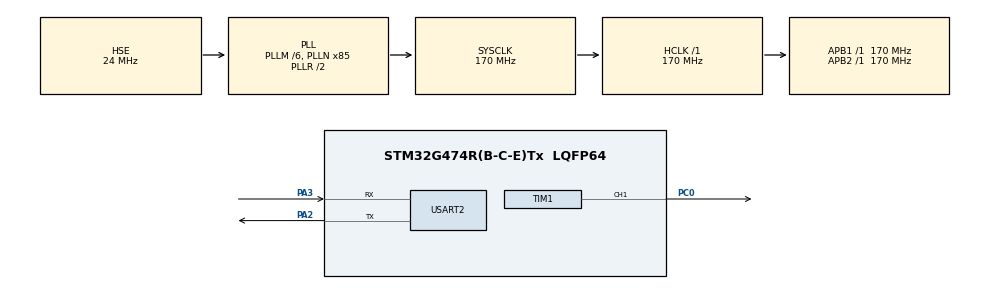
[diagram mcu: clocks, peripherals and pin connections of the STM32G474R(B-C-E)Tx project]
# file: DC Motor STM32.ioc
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Dma.Request0=TIM1_CH1
Dma.Request1=USART2_RX
Dma.Request2=USART2_TX
Dma.TIM1_CH1.0.Direction=DMA_MEMORY_TO_PERIPH
Dma.TIM1_CH1.0.EventEnable=DISABLE
Dma.TIM1_CH1.0.Instance=DMA1_Channel1
Dma.TIM1_CH1.0.MemDataAlignment=DMA_MDATAALIGN_HALFWORD
Dma.TIM1_CH1.0.MemInc=DMA_MINC_ENABLE
Dma.TIM1_CH1.0.Mode=DMA_NORMAL
Dma.TIM1_CH1.0.PeriphDataAlignment=DMA_PDATAALIGN_HALFWORD
Dma.TIM1_CH1.0.PeriphInc=DMA_PINC_DISABLE
Dma.TIM1_CH1.0.Polarity=HAL_DMAMUX_REQ_GEN_RISING
Dma.TIM1_CH1.0.Priority=DMA_PRIORITY_LOW
Dma.TIM1_CH1.0.RequestNumber=1
Dma.TIM1_CH1.0.SignalID=NONE
Dma.TIM1_CH1.0.SyncEnable=DISABLE
Dma.TIM1_CH1.0.SyncPolarity=HAL_DMAMUX_SYNC_NO_EVENT
Dma.TIM1_CH1.0.SyncRequestNumber=1
Dma.TIM1_CH1.0.SyncSignalID=NONE
Dma.USART2_RX.1.Direction=DMA_PERIPH_TO_MEMORY
Dma.USART2_RX.1.EventEnable=DISABLE
Dma.USART2_RX.1.Instance=DMA1_Channel2
Dma.USART2_RX.1.MemDataAlignment=DMA_MDATAALIGN_BYTE
Dma.USART2_RX.1.MemInc=DMA_MINC_ENABLE
Dma.USART2_RX.1.Mode=DMA_NORMAL
Dma.USART2_RX.1.PeriphDataAlignment=DMA_PDATAALIGN_BYTE
Dma.USART2_RX.1.PeriphInc=DMA_PINC_DISABLE
Dma.USART2_RX.1.Polarity=HAL_DMAMUX_REQ_GEN_RISING
Dma.USART2_RX.1.Priority=DMA_PRIORITY_LOW
Dma.USART2_RX.1.RequestNumber=1
Dma.USART2_RX.1.SignalID=NONE
Dma.USART2_RX.1.SyncEnable=DISABLE
Dma.USART2_RX.1.SyncPolarity=HAL_DMAMUX_SYNC_NO_EVENT
Dma.USART2_RX.1.SyncRequestNumber=1
Dma.USART2_RX.1.SyncSignalID=NONE
Dma.USART2_TX.2.Direction=DMA_MEMORY_TO_PERIPH
Dma.USART2_TX.2.EventEnable=DISABLE
Dma.USART2_TX.2.Instance=DMA1_Channel3
Dma.USART2_TX.2.MemDataAlignment=DMA_MDATAALIGN_BYTE
Dma.USART2_TX.2.MemInc=DMA_MINC_ENABLE
Dma.USART2_TX.2.Mode=DMA_NORMAL
Dma.USART2_TX.2.PeriphDataAlignment=DMA_PDATAALIGN_BYTE
Dma.USART2_TX.2.PeriphInc=DMA_PINC_DISABLE
Dma.USART2_TX.2.Polarity=HAL_DMAMUX_REQ_GEN_RISING
Dma.USART2_TX.2.Priority=DMA_PRIORITY_LOW
Dma.USART2_TX.2.RequestNumber=1
Dma.USART2_TX.2.SignalID=NONE
Dma.USART2_TX.2.SyncEnable=DISABLE
Dma.USART2_TX.2.SyncPolarity=HAL_DMAMUX_SYNC_NO_EVENT
Dma.USART2_TX.2.SyncRequestNumber=1
Dma.USART2_TX.2.SyncSignalID=NONE
Mcu.Family=STM32G4
Mcu.Name=STM32G474R(B-C-E)Tx
Mcu.Package=LQFP64
NVIC.DMA1_Channel1_IRQn=true\:0\:0\:false\:false\:true\:false\:true\:true
NVIC.DMA1_Channel2_IRQn=true\:0\:0\:false\:false\:true\:false\:true\:true
NVIC.DMA1_Channel3_IRQn=true\:0\:0\:false\:false\:true\:false\:true\:true
NVIC.PriorityGroup=NVIC_PRIORITYGROUP_4
NVIC.USART2_IRQn=true\:0\:0\:false\:false\:true\:true\:true\:true
PA13.Mode=Serial_Wire
PA13.Signal=SYS_JTMS-SWDIO
PA14.Mode=Serial_Wire
PA14.Signal=SYS_JTCK-SWCLK
PA2.Mode=Asynchronous
PA2.Signal=USART2_TX
PA3.Mode=Asynchronous
PA3.Signal=USART2_RX
PC0.Signal=S_TIM1_CH1
PC14-OSC32_IN.Mode=LSE-External-Oscillator
PC14-OSC32_IN.Signal=RCC_OSC32_IN
PC15-OSC32_OUT.Mode=LSE-External-Oscillator
PC15-OSC32_OUT.Signal=RCC_OSC32_OUT
PF0-OSC_IN.Mode=HSE-External-Oscillator
PF0-OSC_IN.Signal=RCC_OSC_IN
PF1-OSC_OUT.Mode=HSE-External-Oscillator
PF1-OSC_OUT.Signal=RCC_OSC_OUT
ProjectManager.HeapSize=0x200
ProjectManager.StackSize=0x400
ProjectManager.TargetToolchain=STM32CubeIDE
RCC.ADC12Freq_Value=170000000
RCC.ADC345Freq_Value=170000000
RCC.AHBFreq_Value=170000000
RCC.APB1Freq_Value=170000000
RCC.APB1TimFreq_Value=170000000
RCC.APB2Freq_Value=170000000
RCC.APB2TimFreq_Value=170000000
RCC.CortexFreq_Value=170000000
RCC.EXTERNAL_CLOCK_VALUE=12288000
RCC.HCLKFreq_Value=170000000
RCC.HSE_VALUE=24000000
RCC.HSI48_VALUE=48000000
RCC.HSI_VALUE=16000000
RCC.PLLM=RCC_PLLM_DIV6
RCC.PLLN=85
RCC.PLLSourceVirtual=RCC_PLLSOURCE_HSE
RCC.SYSCLKFreq_VALUE=170000000
RCC.SYSCLKSource=RCC_SYSCLKSOURCE_PLLCLK
RCC.USBFreq_Value=170000000
RCC.VCOOutputFreq_Value=340000000
SH.S_TIM1_CH1.0=TIM1_CH1,PWM Generation1 CH1
TIM1.Channel-PWM\ Generation1\ CH1=TIM_CHANNEL_1
TIM1.PeriodNoDither=100
TIM1.Prescaler=170-1
USART2.VirtualMode-Asynchronous=VM_ASYNC
VP_SYS_VS_DBSignals.Mode=DisableDeadBatterySignals
VP_TIM1_VS_ClockSourceINT.Mode=Internal
board=custom

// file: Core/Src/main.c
/* USER CODE BEGIN Header */
/**
  ******************************************************************************
  * @file           : main.c
  * @brief          : Main program body
  ******************************************************************************
  * @attention
  *
  * Copyright (c) 2026 STMicroelectronics.
  * All rights reserved.
  *
  * This software is licensed under terms that can be found in the LICENSE file
  * in the root directory of this software component.
  * If no LICENSE file comes with this software, it is provided AS-IS.
  *
  ******************************************************************************
  */
/* USER CODE END Header */
#include "main.h"

/* USER CODE BEGIN Includes */
#include <stdlib.h>
#include <stdio.h>

/* USER CODE END Includes */

TIM_HandleTypeDef htim1;
DMA_HandleTypeDef hdma_tim1_ch1;

UART_HandleTypeDef huart2;
DMA_HandleTypeDef hdma_usart2_rx;
DMA_HandleTypeDef hdma_usart2_tx;

void SystemClock_Config(void);
static void MX_GPIO_Init(void);
static void MX_DMA_Init(void);
static void MX_TIM1_Init(void);
static void MX_USART2_UART_Init(void);

/* USER CODE BEGIN 0 */

char rxBuf[4]; //Receives input
uint8_t ch; //Buffer to store into rxBuf
uint8_t i; //Index
char txBuf[20]; //Outputs duty cycle
int duty = 0; //Directly changes duty

/* USER CODE END 0 */

int main(void)
{

  /* MCU Configuration--------------------------------------------------------*/

  /* Reset of all peripherals, Initializes the Flash interface and the Systick. */
  HAL_Init();

  /* Configure the system clock */
  SystemClock_Config();

  /* Initialize all configured peripherals */
  MX_GPIO_Init();
  MX_DMA_Init();
  MX_TIM1_Init();
  MX_USART2_UART_Init();
  /* USER CODE BEGIN 2 */

  TIM1 -> CCR1 = duty; //CCR is made to equal to duty variable
  HAL_TIM_PWM_Start(&htim1, TIM_CHANNEL_1); //PWM by itself

  /* USER CODE END 2 */

  /* Infinite loop */
  while (1)
  {

    /* USER CODE BEGIN 3 */
	  HAL_UART_Receive(&huart2, &ch, 1, HAL_MAX_DELAY); //Receives each character
	  if(ch == '\r' ||ch == '\n' ) { //If enter moves to change duty
		  if (i > 0) { //Makes sure it runs when there is at least something in rxBuf
		  rxBuf[i] = '\0'; //Sets the index as \0 to indicate end off.

		  duty = atoi(rxBuf); //Converts rxBuf values to an actual integer

		  if(duty < 0) duty = 0; //Makes sure that program doesnt break by entering less than 0 or more than 100
		  if(duty > 100) duty = 100;

		  int len = snprintf(txBuf, sizeof(txBuf), "Duty Cycle: %d%%\r\n", duty); //snprint returns a length and also reformats txbuf to the string typed

		  HAL_UART_Transmit_DMA(&huart2,(uint8_t *) txBuf, len); //Outputs duty cycle value

		  TIM1 -> CCR1 = duty; //Changes duty cycle

		  i = 0; //Sets indx back to 0 to start again
		  }
	  }

	  else if((ch >= '0') && (ch <= '9')) { //If no enter and want to enter more values

		  if (i < sizeof(rxBuf) - 1) rxBuf[i++] = ch; // makes sure you cant enter more than 3 values and also makes rxBuf = ch
	  }

  }
  /* USER CODE END 3 */
}

void SystemClock_Config(void)
{
  RCC_OscInitTypeDef RCC_OscInitStruct = {0};
  RCC_ClkInitTypeDef RCC_ClkInitStruct = {0};

  /** Configure the main internal regulator output voltage
  */
  HAL_PWREx_ControlVoltageScaling(PWR_REGULATOR_VOLTAGE_SCALE1_BOOST);

  /** Initializes the RCC Oscillators according to the specified parameters
  * in the RCC_OscInitTypeDef structure.
  */
  RCC_OscInitStruct.OscillatorType = RCC_OSCILLATORTYPE_HSE;
  RCC_OscInitStruct.HSEState = RCC_HSE_ON;
  RCC_OscInitStruct.PLL.PLLState = RCC_PLL_ON;
  RCC_OscInitStruct.PLL.PLLSource = RCC_PLLSOURCE_HSE;
  RCC_OscInitStruct.PLL.PLLM = RCC_PLLM_DIV6;
  RCC_OscInitStruct.PLL.PLLN = 85;
  RCC_OscInitStruct.PLL.PLLP = RCC_PLLP_DIV2;
  RCC_OscInitStruct.PLL.PLLQ = RCC_PLLQ_DIV2;
  RCC_OscInitStruct.PLL.PLLR = RCC_PLLR_DIV2;
  if (HAL_RCC_OscConfig(&RCC_OscInitStruct) != HAL_OK)
  {
    Error_Handler();
  }

  /** Initializes the CPU, AHB and APB buses clocks
  */
  RCC_ClkInitStruct.ClockType = RCC_CLOCKTYPE_HCLK|RCC_CLOCKTYPE_SYSCLK
                              |RCC_CLOCKTYPE_PCLK1|RCC_CLOCKTYPE_PCLK2;
  RCC_ClkInitStruct.SYSCLKSource = RCC_SYSCLKSOURCE_PLLCLK;
  RCC_ClkInitStruct.AHBCLKDivider = RCC_SYSCLK_DIV1;
  RCC_ClkInitStruct.APB1CLKDivider = RCC_HCLK_DIV1;
  RCC_ClkInitStruct.APB2CLKDivider = RCC_HCLK_DIV1;

  if (HAL_RCC_ClockConfig(&RCC_ClkInitStruct, FLASH_LATENCY_4) != HAL_OK)
  {
    Error_Handler();
  }
}

static void MX_TIM1_Init(void)
{

  TIM_ClockConfigTypeDef sClockSourceConfig = {0};
  TIM_MasterConfigTypeDef sMasterConfig = {0};
  TIM_OC_InitTypeDef sConfigOC = {0};
  TIM_BreakDeadTimeConfigTypeDef sBreakDeadTimeConfig = {0};

  htim1.Instance = TIM1;
  htim1.Init.Prescaler = 170-1;
  htim1.Init.CounterMode = TIM_COUNTERMODE_UP;
  htim1.Init.Period = 100;
  htim1.Init.ClockDivision = TIM_CLOCKDIVISION_DIV1;
  htim1.Init.RepetitionCounter = 0;
  htim1.Init.AutoReloadPreload = TIM_AUTORELOAD_PRELOAD_DISABLE;
  if (HAL_TIM_Base_Init(&htim1) != HAL_OK)
  {
    Error_Handler();
  }
  sClockSourceConfig.ClockSource = TIM_CLOCKSOURCE_INTERNAL;
  if (HAL_TIM_ConfigClockSource(&htim1, &sClockSourceConfig) != HAL_OK)
  {
    Error_Handler();
  }
  if (HAL_TIM_PWM_Init(&htim1) != HAL_OK)
  {
    Error_Handler();
  }
  sMasterConfig.MasterOutputTrigger = TIM_TRGO_RESET;
  sMasterConfig.MasterOutputTrigger2 = TIM_TRGO2_RESET;
  sMasterConfig.MasterSlaveMode = TIM_MASTERSLAVEMODE_DISABLE;
  if (HAL_TIMEx_MasterConfigSynchronization(&htim1, &sMasterConfig) != HAL_OK)
  {
    Error_Handler();
  }
  sConfigOC.OCMode = TIM_OCMODE_PWM1;
  sConfigOC.Pulse = 0;
  sConfigOC.OCPolarity = TIM_OCPOLARITY_HIGH;
  sConfigOC.OCNPolarity = TIM_OCNPOLARITY_HIGH;
  sConfigOC.OCFastMode = TIM_OCFAST_DISABLE;
  sConfigOC.OCIdleState = TIM_OCIDLESTATE_RESET;
  sConfigOC.OCNIdleState = TIM_OCNIDLESTATE_RESET;
  if (HAL_TIM_PWM_ConfigChannel(&htim1, &sConfigOC, TIM_CHANNEL_1) != HAL_OK)
  {
    Error_Handler();
  }
  sBreakDeadTimeConfig.OffStateRunMode = TIM_OSSR_DISABLE;
  sBreakDeadTimeConfig.OffStateIDLEMode = TIM_OSSI_DISABLE;
  sBreakDeadTimeConfig.LockLevel = TIM_LOCKLEVEL_OFF;
  sBreakDeadTimeConfig.DeadTime = 0;
  sBreakDeadTimeConfig.BreakState = TIM_BREAK_DISABLE;
  sBreakDeadTimeConfig.BreakPolarity = TIM_BREAKPOLARITY_HIGH;
  sBreakDeadTimeConfig.BreakFilter = 0;
  sBreakDeadTimeConfig.BreakAFMode = TIM_BREAK_AFMODE_INPUT;
  sBreakDeadTimeConfig.Break2State = TIM_BREAK2_DISABLE;
  sBreakDeadTimeConfig.Break2Polarity = TIM_BREAK2POLARITY_HIGH;
  sBreakDeadTimeConfig.Break2Filter = 0;
  sBreakDeadTimeConfig.Break2AFMode = TIM_BREAK_AFMODE_INPUT;
  sBreakDeadTimeConfig.AutomaticOutput = TIM_AUTOMATICOUTPUT_DISABLE;
  if (HAL_TIMEx_ConfigBreakDeadTime(&htim1, &sBreakDeadTimeConfig) != HAL_OK)
  {
    Error_Handler();
  }
  HAL_TIM_MspPostInit(&htim1);

}

static void MX_USART2_UART_Init(void)
{

  huart2.Instance = USART2;
  huart2.Init.BaudRate = 115200;
  huart2.Init.WordLength = UART_WORDLENGTH_8B;
  huart2.Init.StopBits = UART_STOPBITS_1;
  huart2.Init.Parity = UART_PARITY_NONE;
  huart2.Init.Mode = UART_MODE_TX_RX;
  huart2.Init.HwFlowCtl = UART_HWCONTROL_NONE;
  huart2.Init.OverSampling = UART_OVERSAMPLING_16;
  huart2.Init.OneBitSampling = UART_ONE_BIT_SAMPLE_DISABLE;
  huart2.Init.ClockPrescaler = UART_PRESCALER_DIV1;
  huart2.AdvancedInit.AdvFeatureInit = UART_ADVFEATURE_NO_INIT;
  if (HAL_UART_Init(&huart2) != HAL_OK)
  {
    Error_Handler();
  }
  if (HAL_UARTEx_SetTxFifoThreshold(&huart2, UART_TXFIFO_THRESHOLD_1_8) != HAL_OK)
  {
    Error_Handler();
  }
  if (HAL_UARTEx_SetRxFifoThreshold(&huart2, UART_RXFIFO_THRESHOLD_1_8) != HAL_OK)
  {
    Error_Handler();
  }
  if (HAL_UARTEx_DisableFifoMode(&huart2) != HAL_OK)
  {
    Error_Handler();
  }

}

static void MX_DMA_Init(void)
{

  /* DMA controller clock enable */
  __HAL_RCC_DMAMUX1_CLK_ENABLE();
  __HAL_RCC_DMA1_CLK_ENABLE();

  /* DMA interrupt init */
  /* DMA1_Channel1_IRQn interrupt configuration */
  HAL_NVIC_SetPriority(DMA1_Channel1_IRQn, 0, 0);
  HAL_NVIC_EnableIRQ(DMA1_Channel1_IRQn);
  /* DMA1_Channel2_IRQn interrupt configuration */
  HAL_NVIC_SetPriority(DMA1_Channel2_IRQn, 0, 0);
  HAL_NVIC_EnableIRQ(DMA1_Channel2_IRQn);
  /* DMA1_Channel3_IRQn interrupt configuration */
  HAL_NVIC_SetPriority(DMA1_Channel3_IRQn, 0, 0);
  HAL_NVIC_EnableIRQ(DMA1_Channel3_IRQn);

}

static void MX_GPIO_Init(void)
{

  /* GPIO Ports Clock Enable */
  __HAL_RCC_GPIOC_CLK_ENABLE();
  __HAL_RCC_GPIOF_CLK_ENABLE();
  __HAL_RCC_GPIOA_CLK_ENABLE();

}

void Error_Handler(void)
{
  __disable_irq();
  while (1)
  {
  }
}
